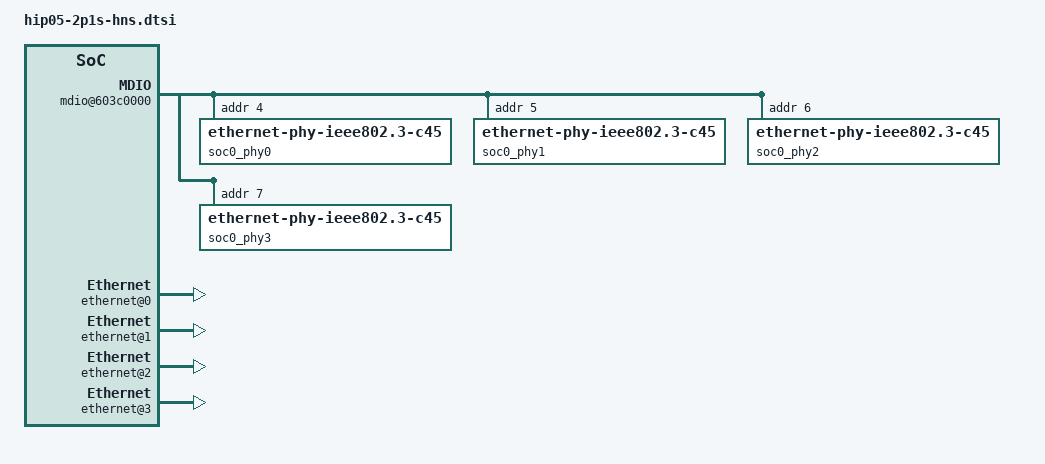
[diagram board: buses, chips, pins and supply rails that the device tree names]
soc0: soc@000000000 {
	#address-cells = <2>;
	#size-cells = <2>;
	device_type = "soc";
	compatible = "simple-bus";
	ranges = <0x0 0x0 0x0 0x0 0x1 0x0>;
	chip-id = <0>;

	mdio@603c0000 {
		#address-cells = <0x1>;
		#size-cells = <0x0>;
		compatible = "hisilicon,mdio";
		reg = <0x0 0x603c0000 0x0 0x10000>;
		subctrl_vbase = <&peri_c_subctrl>;

		soc0_phy0: ethernet-phy@0 {
			reg = <0x4>;
			compatible = "ethernet-phy-ieee802.3-c45";
		};

		soc0_phy1: ethernet-phy@1 {
			reg = <0x5>;
			compatible = "ethernet-phy-ieee802.3-c45";
		};

		soc0_phy2: ethernet-phy@2 {
			reg = <0x6>;
			device_type = "ethernet-phy";
			compatible = "ethernet-phy-ieee802.3-c45";
		};

		soc0_phy3: ethernet-phy@3 {
			reg = <0x7>;
			device_type = "ethernet-phy";
			compatible = "ethernet-phy-ieee802.3-c45";
		};
	};

	dsaf0: dsa@c7000000 {
		compatible = "hisilicon,hns-dsaf-v1";
		mode = "6port-16rss";
		interrupt-parent = <&mbigen_dsa>;

		reg = <0x0 0xC0000000 0x0 0x420000
			0x0 0xC2000000 0x0 0x300000
			0x0 0xc5000000 0x0 0x890000
			0x0 0xc7000000 0x0 0x60000>;
		media-type = "fiber", "fiber", "fiber", "fiber", "unknown",
				"unknown", "unknown", "unknown";
		phy-handle = <&soc0_phy0 &soc0_phy1
				&soc0_phy2 &soc0_phy3
				0 0 0 0>;
		interrupts =
			/* [14] ge fifo err 8 / xge 6**/
				<149 0x4>,
				<150 0x4>,
				<151 0x4>,
				<152 0x4>,
				<153 0x4>,
				<154 0x4>,
				<26 0x4>,
				<27 0x4>,
				<155 0x4>,
				<156 0x4>,
				<157 0x4>,
				<158 0x4>,
				<159 0x4>,
				<160 0x4>,
			/* [12] rcb com 4*3**/
				<6 4>,
				<7 4>,
				<8 4>,
				<9 4>,
				<16 4>,
				<17 4>,
				<18 4>,
				<19 4>,
				<22 4>,
				<23 4>,
				<24 4>,
				<25 4>,
			/* [8] ppe tnl 0-7***/
				<0 4>,
				<1 4>,
				<2 4>,
				<3 4>,
				<4 4>,
				<5 4>,
				<12 4>,
				<13 4>,
			/* [21] dsaf event int 3+18**/
				<128 4>,
				<129 4>,
				<130 4>,
				<0x83 4>,
				<0x84 4>,
				<0x85 4>,
				<0x86 4>,
				<0x87 4>,
				<0x88 4>,
				<0x89 4>,
				<0x8a 4>,
				<0x8b 4>,
				<0x8c 4>,
				<0x8d 4>,
				<0x8e 4>,
				<0x8f 4>,
				<0x90 4>,
				<0x91 4>,
				<0x92 4>,
				<0x93 4>,
				<0x94 4>,
			/* [4] debug rcb 2*2*/
				<14 1>,
				<15 1>,
				<20 1>,
				<21 1>,
			/* [256] sevice rcb 2*128*/
				<0x180 1>,
				<0x181 1>,
				<0x182 1>,
				<0x183 1>,
				<0x184 1>,
				<0x185 1>,
				<0x186 1>,
				<0x187 1>,
				<0x188 1>,
				<0x189 1>,
				<0x18a 1>,
				<0x18b 1>,
				<0x18c 1>,
				<0x18d 1>,
				<0x18e 1>,
				<0x18f 1>,
				<0x190 1>,
				<0x191 1>,
				<0x192 1>,
				<0x193 1>,
				<0x194 1>,
				<0x195 1>,
				<0x196 1>,
				<0x197 1>,
				<0x198 1>,
				<0x199 1>,
				<0x19a 1>,
				<0x19b 1>,
				<0x19c 1>,
				<0x19d 1>,
				<0x19e 1>,
				<0x19f 1>,
				<0x1a0 1>,
				<0x1a1 1>,
				<0x1a2 1>,
				<0x1a3 1>,
				<0x1a4 1>,
				<0x1a5 1>,
				<0x1a6 1>,
				<0x1a7 1>,
				<0x1a8 1>,
				<0x1a9 1>,
				<0x1aa 1>,
				<0x1ab 1>,
				<0x1ac 1>,
				<0x1ad 1>,
				<0x1ae 1>,
				<0x1af 1>,
				<0x1b0 1>,
				<0x1b1 1>,
				<0x1b2 1>,
				<0x1b3 1>,
				<0x1b4 1>,
				<0x1b5 1>,
				<0x1b6 1>,
				<0x1b7 1>,
				<0x1b8 1>,
				<0x1b9 1>,
				<0x1ba 1>,
				<0x1bb 1>,
				<0x1bc 1>,
				<0x1bd 1>,
				<0x1be 1>,
				<0x1bf 1>,
				<0x1c0 1>,
				<0x1c1 1>,
				<0x1c2 1>,
				<0x1c3 1>,
				<0x1c4 1>,
				<0x1c5 1>,
				<0x1c6 1>,
				<0x1c7 1>,
				<0x1c8 1>,
				<0x1c9 1>,
				<0x1ca 1>,
				<0x1cb 1>,
				<0x1cc 1>,
				<0x1cd 1>,
				<0x1ce 1>,
				<0x1cf 1>,
				<0x1d0 1>,
				<0x1d1 1>,
				<0x1d2 1>,
				<0x1d3 1>,
				<0x1d4 1>,
				<0x1d5 1>,
				<0x1d6 1>,
				<0x1d7 1>,
				<0x1d8 1>,
				<0x1d9 1>,
				<0x1da 1>,
				<0x1db 1>,
				<0x1dc 1>,
				<0x1dd 1>,
				<0x1de 1>,
				<0x1df 1>,
				<0x1e0 1>,
				<0x1e1 1>,
				<0x1e2 1>,
				<0x1e3 1>,
				<0x1e4 1>,
				<0x1e5 1>,
				<0x1e6 1>,
				<0x1e7 1>,
				<0x1e8 1>,
				<0x1e9 1>,
				<0x1ea 1>,
				<0x1eb 1>,
				<0x1ec 1>,
				<0x1ed 1>,
				<0x1ee 1>,
				<0x1ef 1>,
				<0x1f0 1>,
				<0x1f1 1>,
				<0x1f2 1>,
				<0x1f3 1>,
				<0x1f4 1>,
				<0x1f5 1>,
				<0x1f6 1>,
				<0x1f7 1>,
				<0x1f8 1>,
				<0x1f9 1>,
				<0x1fa 1>,
				<0x1fb 1>,
				<0x1fc 1>,
				<0x1fd 1>,
				<0x1fe 1>,
				<0x1ff 1>,
				<0x200 1>,
				<0x201 1>,
				<0x202 1>,
				<0x203 1>,
				<0x204 1>,
				<0x205 1>,
				<0x206 1>,
				<0x207 1>,
				<0x208 1>,
				<0x209 1>,
				<0x20a 1>,
				<0x20b 1>,
				<0x20c 1>,
				<0x20d 1>,
				<0x20e 1>,
				<0x20f 1>,
				<0x210 1>,
				<0x211 1>,
				<0x212 1>,
				<0x213 1>,
				<0x214 1>,
				<0x215 1>,
				<0x216 1>,
				<0x217 1>,
				<0x218 1>,
				<0x219 1>,
				<0x21a 1>,
				<0x21b 1>,
				<0x21c 1>,
				<0x21d 1>,
				<0x21e 1>,
				<0x21f 1>,
				<0x220 1>,
				<0x221 1>,
				<0x222 1>,
				<0x223 1>,
				<0x224 1>,
				<0x225 1>,
				<0x226 1>,
				<0x227 1>,
				<0x228 1>,
				<0x229 1>,
				<0x22a 1>,
				<0x22b 1>,
				<0x22c 1>,
				<0x22d 1>,
				<0x22e 1>,
				<0x22f 1>,
				<0x230 1>,
				<0x231 1>,
				<0x232 1>,
				<0x233 1>,
				<0x234 1>,
				<0x235 1>,
				<0x236 1>,
				<0x237 1>,
				<0x238 1>,
				<0x239 1>,
				<0x23a 1>,
				<0x23b 1>,
				<0x23c 1>,
				<0x23d 1>,
				<0x23e 1>,
				<0x23f 1>,
				<0x240 1>,
				<0x241 1>,
				<0x242 1>,
				<0x243 1>,
				<0x244 1>,
				<0x245 1>,
				<0x246 1>,
				<0x247 1>,
				<0x248 1>,
				<0x249 1>,
				<0x24a 1>,
				<0x24b 1>,
				<0x24c 1>,
				<0x24d 1>,
				<0x24e 1>,
				<0x24f 1>,
				<0x250 1>,
				<0x251 1>,
				<0x252 1>,
				<0x253 1>,
				<0x254 1>,
				<0x255 1>,
				<0x256 1>,
				<0x257 1>,
				<0x258 1>,
				<0x259 1>,
				<0x25a 1>,
				<0x25b 1>,
				<0x25c 1>,
				<0x25d 1>,
				<0x25e 1>,
				<0x25f 1>,
				<0x260 1>,
				<0x261 1>,
				<0x262 1>,
				<0x263 1>,
				<0x264 1>,
				<0x265 1>,
				<0x266 1>,
				<0x267 1>,
				<0x268 1>,
				<0x269 1>,
				<0x26a 1>,
				<0x26b 1>,
				<0x26c 1>,
				<0x26d 1>,
				<0x26e 1>,
				<0x26f 1>,
				<0x270 1>,
				<0x271 1>,
				<0x272 1>,
				<0x273 1>,
				<0x274 1>,
				<0x275 1>,
				<0x276 1>,
				<0x277 1>,
				<0x278 1>,
				<0x279 1>,
				<0x27a 1>,
				<0x27b 1>,
				<0x27c 1>,
				<0x27d 1>,
				<0x27e 1>,
				<0x27f 1>;
		buf-size = <4096>;
		desc-num = <1024>;
		dma-coherent;
	};

	ethernet@0{
		compatible = "hisilicon,hns-nic-v1";
		ae-handle = <&dsaf0>;
		port-id = <2>;
		local-mac-address = [00 00 00 01 00 58];
		dma-coherent;
	};
	ethernet@1{
		compatible = "hisilicon,hns-nic-v1";
		ae-handle = <&dsaf0>;
		port-id = <3>;
		local-mac-address = [00 00 00 01 00 59];
		dma-coherent;
	};
	ethernet@2{
		compatible = "hisilicon,hns-nic-v1";
		ae-handle = <&dsaf0>;
		port-id = <4>;
		local-mac-address = [00 00 00 01 00 5a];
		dma-coherent;
	};
	ethernet@3{
		compatible = "hisilicon,hns-nic-v1";
		ae-handle = <&dsaf0>;
		port-id = <5>;
		local-mac-address = [00 00 00 01 00 5b];
		dma-coherent;
	};
};
